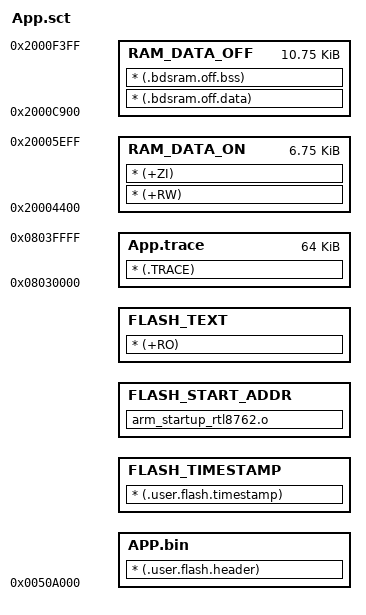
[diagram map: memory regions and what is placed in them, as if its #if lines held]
#! armcc -E
#include "..\..\..\Include\platform\device_name.h"
; *************************************************************
; *** Scatter-Loading Description File generated by uVision ***
; *************************************************************

#define FLASH_ADR  0x0050A000 
#define FLASH_SIZE 0x19000

#ifdef RTL8762AX_VA
    #define RAM_ON_ADR 0x20005400
    #define RAM_ON_SIZE 0xB00
    
    #define RAM_OFF_ADR 0x2000CF00
    #define RAM_OFF_SIZE 0x2500
#endif

#ifdef RTL8762AX_VB
    #define RAM_ON_ADR 0x20004400
    #define RAM_ON_SIZE 0x1B00
    
    #define RAM_OFF_ADR 0x2000C900
    #define RAM_OFF_SIZE 0x2B00
#endif

LOAD_FLASH FLASH_ADR FLASH_SIZE ; 100K
{
    ;FLASH_HEADER +0 ;12Bytes
    APP.bin +0 ;12Bytes
    {
         * (.user.flash.header)  
    }

    FLASH_TIMESTAMP +0  ;32Bytes
    {
        * (.user.flash.timestamp)
    }
	
    FLASH_START_ADDR +0;
    {
        ;* (.user.flash.start)
        ;* (.vectors_table)
        arm_startup_rtl8762.o ; (Reset_Handler, +First)
    }

    FLASH_TEXT +0
    {
        * (+RO)
    }
    
    RAM_DATA_ON RAM_ON_ADR RAM_ON_SIZE
    {
        * (+RW)
        * (+ZI)
    }
	
	RAM_DATA_OFF RAM_OFF_ADR RAM_OFF_SIZE
	{
		* (.bdsram.off.data)
		* (.bdsram.off.bss)
	}
}

LOAD_APP_TRACE 0x08030000 0x10000
{ 
   App.trace 0x08030000 0x10000
   { 
       * (.TRACE) 
   }
}
